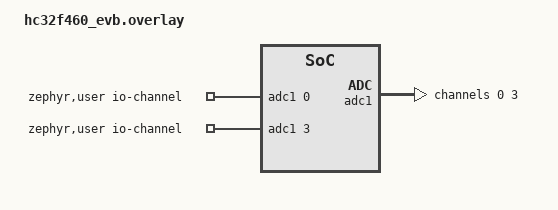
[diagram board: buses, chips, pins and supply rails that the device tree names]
/ {
	zephyr,user {
		io-channels = <&adc1 0>, <&adc1 3>;
	};
};

&adc1 {
	#address-cells = <1>;
	#size-cells = <0>;

	channel@0 {
		reg = <0>;
		zephyr,gain = "ADC_GAIN_1";
		zephyr,reference = "ADC_REF_INTERNAL";
		zephyr,acquisition-time = <0>;
		zephyr,resolution = <12>;
	};
};

&dma1 {
	status = "okay";
};

&adc1 {
	channel@3 {
		reg = <3>;
		zephyr,gain = "ADC_GAIN_1";
		zephyr,reference = "ADC_REF_INTERNAL";
		zephyr,acquisition-time = <0>;
		zephyr,resolution = <12>;
	};

	status = "okay";

	pinctrl-0 = <&adc1_ch0_default>, <&adc1_ch3_default>;
	pinctrl-names = "default";

	dmas =  <&dma1 2 EVT_SRC_ADC1_EOCA (HC32_DMA_PERIPH_TO_MEMORY | \
				HC32_DMA_SOURCE_ADDR_FIX | HC32_DMA_DEST_ADDR_INC | \
				HC32_DMA_DATA_WIDTH_16BIT)>;
	dma-names = "read";
};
